AUTOSAR XML (schema 4-2-1)
package /ComponentTypes
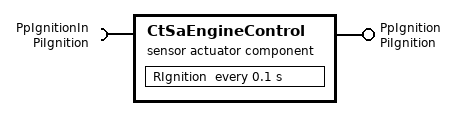
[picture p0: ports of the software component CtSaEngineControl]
  sensor actuator sw component type CtSaEngineControl
    provide port PpIgnition: nonqueued-sender-com-spec{data-element=DeIgnition, init-value=constant-reference=CIgnition}, provided-interface=PiIgnition
    require port PpIgnitionIn: nonqueued-receiver-com-spec{data-element=DeIgnition, filter=data-filter-type=ALWAYS, init-value=constant-reference=CIgnition}, required-interface=PiIgnition
    behavior CtSaEngineControl_InternalBehavior: data-type-mapping=ApMappingSet
      timing event TMT_RIgnition: start-on-event=RIgnition, period=0.1
      runnable RIgnition
        data-receive-point-by-arguments:
          access REC_PpIgnitionIn_DeIgnition: accessed-variable=PpIgnitionIn.DeIgnition
        data-send-points:
          access SEND_PpIgnition_DeIgnition: accessed-variable=PpIgnition.DeIgnition
  swc implementation CtSaEngineControl_Implementation: behavior=CtSaEngineControl_InternalBehavior
    code-descriptors:
      code Default: artifact-descriptors=autosar-engineering-object={short-label=Default, category=SWSRC}
